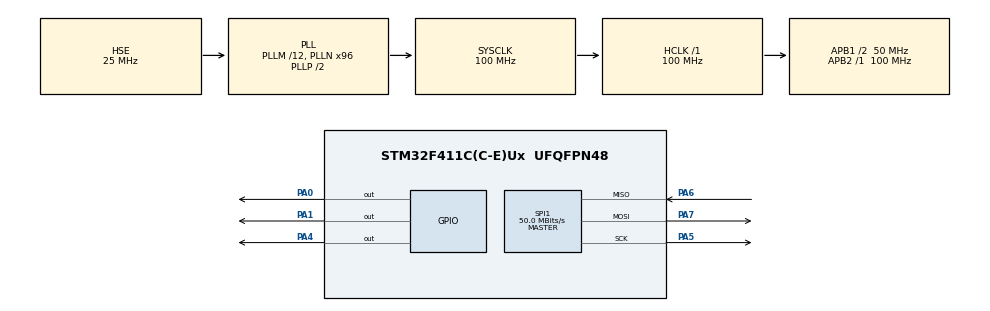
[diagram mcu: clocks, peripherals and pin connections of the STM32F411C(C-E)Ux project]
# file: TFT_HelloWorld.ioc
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Mcu.Family=STM32F4
Mcu.Name=STM32F411C(C-E)Ux
Mcu.Package=UFQFPN48
NVIC.PriorityGroup=NVIC_PRIORITYGROUP_4
PA0-WKUP.PinState=GPIO_PIN_SET
PA0-WKUP.Signal=GPIO_Output
PA1.PinState=GPIO_PIN_SET
PA1.Signal=GPIO_Output
PA13.Mode=Serial_Wire
PA13.Signal=SYS_JTMS-SWDIO
PA14.Mode=Serial_Wire
PA14.Signal=SYS_JTCK-SWCLK
PA4.PinState=GPIO_PIN_SET
PA4.Signal=GPIO_Output
PA5.Mode=Full_Duplex_Master
PA5.Signal=SPI1_SCK
PA6.Mode=Full_Duplex_Master
PA6.Signal=SPI1_MISO
PA7.Mode=Full_Duplex_Master
PA7.Signal=SPI1_MOSI
PH0\ -\ OSC_IN.Mode=HSE-External-Oscillator
PH0\ -\ OSC_IN.Signal=RCC_OSC_IN
PH1\ -\ OSC_OUT.Mode=HSE-External-Oscillator
PH1\ -\ OSC_OUT.Signal=RCC_OSC_OUT
ProjectManager.HeapSize=0x200
ProjectManager.StackSize=0x400
ProjectManager.TargetToolchain=STM32CubeIDE
RCC.48MHZClocksFreq_Value=50000000
RCC.AHBFreq_Value=100000000
RCC.APB1CLKDivider=RCC_HCLK_DIV2
RCC.APB1Freq_Value=50000000
RCC.APB1TimFreq_Value=100000000
RCC.APB2Freq_Value=100000000
RCC.APB2TimFreq_Value=100000000
RCC.CortexFreq_Value=100000000
RCC.HCLKFreq_Value=100000000
RCC.HSE_VALUE=25000000
RCC.HSI_VALUE=16000000
RCC.LSE_VALUE=32768
RCC.PLLM=12
RCC.PLLN=96
RCC.PLLSourceVirtual=RCC_PLLSOURCE_HSE
RCC.SYSCLKFreq_VALUE=100000000
RCC.SYSCLKSource=RCC_SYSCLKSOURCE_PLLCLK
RCC.VCOOutputFreq_Value=200000000
SPI1.BaudRatePrescaler=SPI_BAUDRATEPRESCALER_2
SPI1.CalculateBaudRate=50.0 MBits/s
SPI1.Direction=SPI_DIRECTION_2LINES
SPI1.Mode=SPI_MODE_MASTER
SPI1.VirtualType=VM_MASTER
board=custom

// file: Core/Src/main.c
/* USER CODE BEGIN Header */
/**
  ******************************************************************************
  * @file           : main.c
  * @brief          : Main program body
  ******************************************************************************
  * @attention
  *
  * Copyright (c) 2025 STMicroelectronics.
  * All rights reserved.
  *
  * This software is licensed under terms that can be found in the LICENSE file
  * in the root directory of this software component.
  * If no LICENSE file comes with this software, it is provided AS-IS.
  *
  ******************************************************************************
  */
/* USER CODE END Header */
#include "main.h"
#include "tft_display.h"
#include "image.h"
#include "touch.h"
#include <string.h>

SPI_HandleTypeDef hspi1;

// Conversation messages structure
typedef struct {
    const char* sender;
    const char* message;
    uint16_t color;
} ChatMessage;

// Conversation data
const ChatMessage conversation[] = {
    {"Alice", "Hey! How's your project going?", TFT_CYAN},
    {"Bob", "It's going great! Just finished the TFT display driver.", TFT_GREEN},
    {"Alice", "Wow, that's awesome! Can it show images?", TFT_CYAN},
    {"Bob", "Yes! And text with different colors and sizes.", TFT_GREEN},
    {"Alice", "Perfect! Let me test the conversation display...", TFT_CYAN},
    {"Bob", "Looks like it's working! 🎉", TFT_GREEN},
    {"System", "Conversation display test completed successfully!", TFT_YELLOW}
};

#define NUM_MESSAGES (sizeof(conversation) / sizeof(conversation[0]))

// Background buffers for text - ADD THESE DECLARATIONS
#define TEXT_BUFFER_SIZE 500 // Enough for medium text
uint16_t text_bg_buffer[TEXT_BUFFER_SIZE];

void DisplayConversation(void);
void TouchDemo(void);

void SystemClock_Config(void);
static void MX_GPIO_Init(void);
static void MX_SPI1_Init(void);

/* USER CODE BEGIN 0 */
//

//void DisplayScaledTextDemo(void);
//void AnimatedTextDemo(void);

/* USER CODE END 0 */

int main(void)
{

  HAL_Init();

  /* Configure the system clock */
  SystemClock_Config();

  /* Initialize all configured peripherals */
  MX_GPIO_Init();
  MX_SPI1_Init();
  /* USER CODE BEGIN 2 */

  TFT_Init();
  TOUCH_Init();

  TFT_SetRotation(TFT_ROTATION_90);
  TOUCH_SetOrientation(TOUCH_PORTRAIT);
  TFT_InvertColors(FALSE);
  /* USER CODE END 2 */

  while (1)
  {

      TouchDemo();
//      HAL_Delay(10);

      DisplayConversation();
      HAL_Delay(5000); // Wait 5 seconds before restarting conversation

  }

  /* USER CODE END 3 */
}

void TouchDemo(void) {
    static uint16_t last_x = 0, last_y = 0;
    Touch_State touch;

    if (TOUCH_GetState(&touch)) {
        if (touch.pressed) {
            // Draw touch point
            TFT_DrawFilledRect(touch.x - 2, touch.y - 2, 5, 5, TFT_RED);

            // Display coordinates
            TFT_printf(10, 10, TFT_WHITE, TFT_BLACK, 1,
                      "X: %3d Y: %3d     ", touch.x, touch.y);

            // Draw line from last point
            if (last_x != 0 && last_y != 0) {
                TFT_DrawLine(last_x, last_y, touch.x, touch.y, TFT_GREEN);
            }

            last_x = touch.x;
            last_y = touch.y;
        } else {
            // Touch released
            TFT_printf(10, 25, TFT_WHITE, TFT_BLACK, 1, "Released!        ");
            last_x = 0;
            last_y = 0;
        }
    }
}

void DisplayConversation(void) {
    uint16_t start_y = 30;
    uint16_t bubble_width = 200;
    uint16_t bubble_height = 45;
    uint16_t bubble_spacing = 5;
    uint16_t text_padding = 8;

    // Display background image
    TFT_BackgroundImage(0, 0, imageA1, TFT_HEIGHT_LANDSCAPE, TFT_WIDTH_LANDSCAPE);

    // Display conversation title
    TFT_printf(10, 5, TFT_WHITE, TRANSPARENT, 2, "Conversations");
    TFT_DrawRect(5, 0, TFT_WIDTH_LANDSCAPE - 10, 25, TFT_WHITE);

    // Display each message in the conversation
    for (int i = 0; i < NUM_MESSAGES; i++) {
        uint16_t current_y = start_y + (i * (bubble_height + bubble_spacing));

        // Alternate between left and right alignment for visual effect
        uint16_t bubble_x;
        uint16_t text_x;
        uint16_t bubble_color;

        if (i % 2 == 0) {
            // Left side (Alice/System)
            bubble_x = 10;
            text_x = bubble_x + text_padding;
            bubble_color = TFT_BLUE;
        } else {
            // Right side (Bob)
            bubble_x = TFT_WIDTH_LANDSCAPE - bubble_width - 10;
            text_x = bubble_x + text_padding;
            bubble_color = TFT_RED;
        }

        // Draw message bubble
        TFT_DrawFilledRect(bubble_x, current_y, bubble_width, bubble_height, bubble_color);
        TFT_DrawRect(bubble_x, current_y, bubble_width, bubble_height, TFT_WHITE);

        // Draw sender name
        TFT_printf(text_x, current_y + 4, TFT_WHITE, TRANSPARENT, 1, "%s:", conversation[i].sender);

        // Draw message text (wrap if needed)
        const char* message = conversation[i].message;
        uint16_t msg_width, msg_height;
        TFT_CalculateTextSize(message, 2, &msg_width, &msg_height);

        if (msg_width > (bubble_width - text_padding * 2)) {
            // Message is too long, split into two lines
            char line1[64] = {0};
            char line2[64] = {0};
            int split_pos = 0;

            // Find a good split point (space character)
            for (int j = bubble_width / 12; j > 0; j--) { // Approximate character count
                if (message[j] == ' ') {
                    split_pos = j;
                    break;
                }
            }

            if (split_pos > 0) {
                strncpy(line1, message, split_pos);
                strcpy(line2, message + split_pos + 1);

                TFT_printf(text_x, current_y + 16, conversation[i].color, TRANSPARENT, 1, "%s", line1);
                TFT_printf(text_x, current_y + 30, conversation[i].color, TRANSPARENT, 1, "%s", line2);
            } else {
                // No space found, just truncate
                TFT_printf(text_x, current_y + 20, conversation[i].color, TRANSPARENT, 1, "%.*s...",
                          (bubble_width - text_padding * 2) / 12, message);
            }
        } else {
            // Message fits in one line
            TFT_printf(text_x, current_y + 20, conversation[i].color, TRANSPARENT, 1, "%s", message);
        }

        // Small delay between messages for animation effect
        HAL_Delay(800);
    }

    // Display footer with status
    TFT_DrawFilledRect(5, TFT_HEIGHT_LANDSCAPE - 25, TFT_WIDTH_LANDSCAPE - 10, 20, TFT_BLACK);
    TFT_printf(10, TFT_HEIGHT_LANDSCAPE - 20, TFT_GREEN, TRANSPARENT, 1,
               "Messages: %d | Tap to continue...", NUM_MESSAGES);

    // Draw some decorative elements
    TFT_DrawSymbol(280, TFT_HEIGHT_LANDSCAPE - 40, HEART, TFT_RED, 2);
    TFT_DrawSymbol(300, TFT_HEIGHT_LANDSCAPE - 40, SMILEY_FACE, TFT_YELLOW, 2);
}

void SystemClock_Config(void)
{
  RCC_OscInitTypeDef RCC_OscInitStruct = {0};
  RCC_ClkInitTypeDef RCC_ClkInitStruct = {0};

  /** Configure the main internal regulator output voltage
  */
  __HAL_RCC_PWR_CLK_ENABLE();
  __HAL_PWR_VOLTAGESCALING_CONFIG(PWR_REGULATOR_VOLTAGE_SCALE1);

  /** Initializes the RCC Oscillators according to the specified parameters
  * in the RCC_OscInitTypeDef structure.
  */
  RCC_OscInitStruct.OscillatorType = RCC_OSCILLATORTYPE_HSE;
  RCC_OscInitStruct.HSEState = RCC_HSE_ON;
  RCC_OscInitStruct.PLL.PLLState = RCC_PLL_ON;
  RCC_OscInitStruct.PLL.PLLSource = RCC_PLLSOURCE_HSE;
  RCC_OscInitStruct.PLL.PLLM = 12;
  RCC_OscInitStruct.PLL.PLLN = 96;
  RCC_OscInitStruct.PLL.PLLP = RCC_PLLP_DIV2;
  RCC_OscInitStruct.PLL.PLLQ = 4;
  if (HAL_RCC_OscConfig(&RCC_OscInitStruct) != HAL_OK)
  {
    Error_Handler();
  }

  /** Initializes the CPU, AHB and APB buses clocks
  */
  RCC_ClkInitStruct.ClockType = RCC_CLOCKTYPE_HCLK|RCC_CLOCKTYPE_SYSCLK
                              |RCC_CLOCKTYPE_PCLK1|RCC_CLOCKTYPE_PCLK2;
  RCC_ClkInitStruct.SYSCLKSource = RCC_SYSCLKSOURCE_PLLCLK;
  RCC_ClkInitStruct.AHBCLKDivider = RCC_SYSCLK_DIV1;
  RCC_ClkInitStruct.APB1CLKDivider = RCC_HCLK_DIV2;
  RCC_ClkInitStruct.APB2CLKDivider = RCC_HCLK_DIV1;

  if (HAL_RCC_ClockConfig(&RCC_ClkInitStruct, FLASH_LATENCY_3) != HAL_OK)
  {
    Error_Handler();
  }
}

static void MX_SPI1_Init(void)
{

  /* SPI1 parameter configuration*/
  hspi1.Instance = SPI1;
  hspi1.Init.Mode = SPI_MODE_MASTER;
  hspi1.Init.Direction = SPI_DIRECTION_2LINES;
  hspi1.Init.DataSize = SPI_DATASIZE_8BIT;
  hspi1.Init.CLKPolarity = SPI_POLARITY_LOW;
  hspi1.Init.CLKPhase = SPI_PHASE_1EDGE;
  hspi1.Init.NSS = SPI_NSS_SOFT;
  hspi1.Init.BaudRatePrescaler = SPI_BAUDRATEPRESCALER_2;
  hspi1.Init.FirstBit = SPI_FIRSTBIT_MSB;
  hspi1.Init.TIMode = SPI_TIMODE_DISABLE;
  hspi1.Init.CRCCalculation = SPI_CRCCALCULATION_DISABLE;
  hspi1.Init.CRCPolynomial = 10;
  if (HAL_SPI_Init(&hspi1) != HAL_OK)
  {
    Error_Handler();
  }

}

static void MX_GPIO_Init(void)
{
  GPIO_InitTypeDef GPIO_InitStruct = {0};

  /* GPIO Ports Clock Enable */
  __HAL_RCC_GPIOH_CLK_ENABLE();
  __HAL_RCC_GPIOA_CLK_ENABLE();

  /*Configure GPIO pin Output Level */
  HAL_GPIO_WritePin(GPIOA, GPIO_PIN_0|GPIO_PIN_1|GPIO_PIN_4, GPIO_PIN_SET);

  /*Configure GPIO pins : PA0 PA1 PA4 */
  GPIO_InitStruct.Pin = GPIO_PIN_0|GPIO_PIN_1|GPIO_PIN_4;
  GPIO_InitStruct.Mode = GPIO_MODE_OUTPUT_PP;
  GPIO_InitStruct.Pull = GPIO_NOPULL;
  GPIO_InitStruct.Speed = GPIO_SPEED_FREQ_LOW;
  HAL_GPIO_Init(GPIOA, &GPIO_InitStruct);

}

void Error_Handler(void)
{
  __disable_irq();
  while (1)
  {
  }
}
